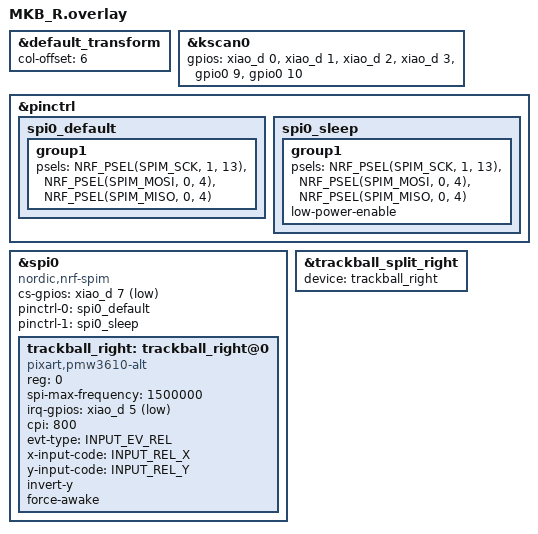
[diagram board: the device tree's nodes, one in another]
#include "MKB.dtsi"
#include <zephyr/dt-bindings/input/input-event-codes.h>

&default_transform {
    col-offset = <6>;
};

&kscan0 {
  gpios
      = <&xiao_d  0 (GPIO_ACTIVE_HIGH)>
      , <&xiao_d  1 (GPIO_ACTIVE_HIGH)>
      , <&xiao_d  2 (GPIO_ACTIVE_HIGH)>
      , <&xiao_d  3 (GPIO_ACTIVE_HIGH)>
      , <&gpio0   9 (GPIO_ACTIVE_HIGH)>
      , <&gpio0  10 (GPIO_ACTIVE_HIGH)>
      ;
};



&pinctrl {
    spi0_default: spi0_default {
        group1 {
            psels = <NRF_PSEL(SPIM_SCK,  1, 13)>,
                    <NRF_PSEL(SPIM_MOSI, 0, 4)>,
                    <NRF_PSEL(SPIM_MISO, 0, 4)>;
        };
    };

    spi0_sleep: spi0_sleep {
        group1 {
            psels = <NRF_PSEL(SPIM_SCK,  1, 13)>,
                    <NRF_PSEL(SPIM_MOSI, 0, 4)>,
                    <NRF_PSEL(SPIM_MISO, 0, 4)>;
            low-power-enable;
        };
    };
};


&spi0 {
    status = "okay";
    cs-gpios =  <&xiao_d 7 GPIO_ACTIVE_LOW>;
    pinctrl-0 = <&spi0_default>;
    pinctrl-1 = <&spi0_sleep>;
    pinctrl-names = "default", "sleep";
    compatible = "nordic,nrf-spim";

    trackball_right: trackball_right@0 {
        status = "okay";
        compatible = "pixart,pmw3610-alt";
        reg = <0>;
        spi-max-frequency = <1500000>;
        irq-gpios = <&xiao_d 5 (GPIO_ACTIVE_LOW | GPIO_PULL_UP)>;
        cpi = <800>;
        evt-type = <INPUT_EV_REL>;
        x-input-code = <INPUT_REL_X>;
        y-input-code = <INPUT_REL_Y>;
        // swap-xy;
        // invert-x;
        invert-y;
        force-awake;
    };
};

/delete-node/ &trackball_right_listener;
/delete-node/ &trackball_left_listener;
/delete-node/ &trackball_split_left;

&trackball_split_right {
    device = <&trackball_right>;
};
